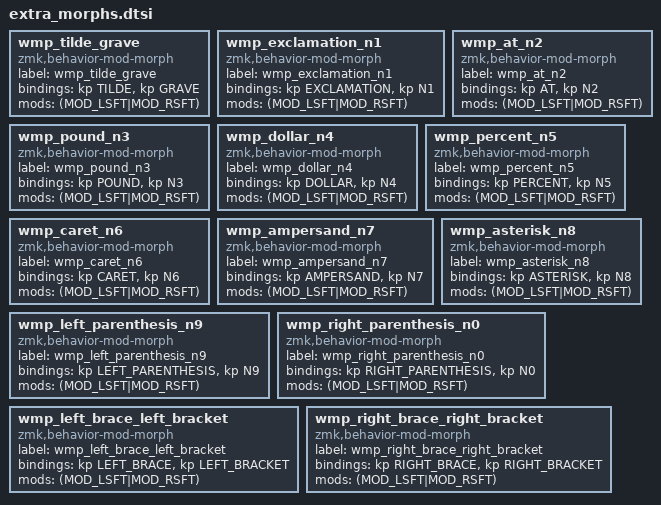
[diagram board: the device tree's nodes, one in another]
wmp_tilde_grave: wmp_tilde_grave {
    compatible = "zmk,behavior-mod-morph";
    label = "wmp_tilde_grave";
    #binding-cells = <0>;
    bindings = <&kp TILDE>, <&kp GRAVE>;
    mods = <(MOD_LSFT|MOD_RSFT)>;
};
wmp_exclamation_n1: wmp_exclamation_n1 {
    compatible = "zmk,behavior-mod-morph";
    label = "wmp_exclamation_n1";
    #binding-cells = <0>;
    bindings = <&kp EXCLAMATION>, <&kp N1>;
    mods = <(MOD_LSFT|MOD_RSFT)>;
};
wmp_at_n2: wmp_at_n2 {
    compatible = "zmk,behavior-mod-morph";
    label = "wmp_at_n2";
    #binding-cells = <0>;
    bindings = <&kp AT>, <&kp N2>;
    mods = <(MOD_LSFT|MOD_RSFT)>;
};
wmp_pound_n3: wmp_pound_n3 {
    compatible = "zmk,behavior-mod-morph";
    label = "wmp_pound_n3";
    #binding-cells = <0>;
    bindings = <&kp POUND>, <&kp N3>;
    mods = <(MOD_LSFT|MOD_RSFT)>;
};
wmp_dollar_n4: wmp_dollar_n4 {
    compatible = "zmk,behavior-mod-morph";
    label = "wmp_dollar_n4";
    #binding-cells = <0>;
    bindings = <&kp DOLLAR>, <&kp N4>;
    mods = <(MOD_LSFT|MOD_RSFT)>;
};
wmp_percent_n5: wmp_percent_n5 {
    compatible = "zmk,behavior-mod-morph";
    label = "wmp_percent_n5";
    #binding-cells = <0>;
    bindings = <&kp PERCENT>, <&kp N5>;
    mods = <(MOD_LSFT|MOD_RSFT)>;
};
wmp_caret_n6: wmp_caret_n6 {
    compatible = "zmk,behavior-mod-morph";
    label = "wmp_caret_n6";
    #binding-cells = <0>;
    bindings = <&kp CARET>, <&kp N6>;
    mods = <(MOD_LSFT|MOD_RSFT)>;
};
wmp_ampersand_n7: wmp_ampersand_n7 {
    compatible = "zmk,behavior-mod-morph";
    label = "wmp_ampersand_n7";
    #binding-cells = <0>;
    bindings = <&kp AMPERSAND>, <&kp N7>;
    mods = <(MOD_LSFT|MOD_RSFT)>;
};
wmp_asterisk_n8: wmp_asterisk_n8 {
    compatible = "zmk,behavior-mod-morph";
    label = "wmp_asterisk_n8";
    #binding-cells = <0>;
    bindings = <&kp ASTERISK>, <&kp N8>;
    mods = <(MOD_LSFT|MOD_RSFT)>;
};
wmp_left_parenthesis_n9: wmp_left_parenthesis_n9 {
    compatible = "zmk,behavior-mod-morph";
    label = "wmp_left_parenthesis_n9";
    #binding-cells = <0>;
    bindings = <&kp LEFT_PARENTHESIS>, <&kp N9>;
    mods = <(MOD_LSFT|MOD_RSFT)>;
};
wmp_right_parenthesis_n0: wmp_right_parenthesis_n0 {
    compatible = "zmk,behavior-mod-morph";
    label = "wmp_right_parenthesis_n0";
    #binding-cells = <0>;
    bindings = <&kp RIGHT_PARENTHESIS>, <&kp N0>;
    mods = <(MOD_LSFT|MOD_RSFT)>;
};
wmp_left_brace_left_bracket: wmp_left_brace_left_bracket {
    compatible = "zmk,behavior-mod-morph";
    label = "wmp_left_brace_left_bracket";
    #binding-cells = <0>;
    bindings = <&kp LEFT_BRACE>, <&kp LEFT_BRACKET>;
    mods = <(MOD_LSFT|MOD_RSFT)>;
};
wmp_right_brace_right_bracket: wmp_right_brace_right_bracket {
    compatible = "zmk,behavior-mod-morph";
    label = "wmp_right_brace_right_bracket";
    #binding-cells = <0>;
    bindings = <&kp RIGHT_BRACE>, <&kp RIGHT_BRACKET>;
    mods = <(MOD_LSFT|MOD_RSFT)>;
};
